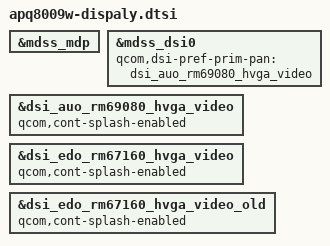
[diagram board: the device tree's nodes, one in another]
/* Copyright (c) 2016,  HUAWEI TECHNOLOGIES CO., LTD.  All rights reserved.
 *
 * This program is free software; you can redistribute it and/or modify
 * it under the terms of the GNU General Public License version 2 and
 * only version 2 as published by the Free Software Foundation.
 *
 * This program is distributed in the hope that it will be useful,
 * but WITHOUT ANY WARRANTY; without even the implied warranty of
 * MERCHANTABILITY or FITNESS FOR A PARTICULAR PURPOSE.  See the
 * GNU General Public License for more details.
 */

#include "dsi-panel-edo-rm67160-hvga-video.dtsi"
#include "dsi-panel-auo-rm69080-hvga-video.dtsi"
#include "dsi-panel-edo-rm67160-hvga-video-old.dtsi"

/*delete the qcom dispaly dtsi*/
&mdss_mdp {
    /delete-node/ dsi_hx8394d_480_vid;
    /delete-node/ dsi_hx8394d_720_vid;
    /delete-node/ dsi_hx8394d_qhd_vid;

    /delete-node/ dsi_auo_cx_qvga_cmd;
    /delete-node/ dsi_auo_qvga_cmd;
    /delete-node/ dsi_hx8394d_480_vid;
    /delete-node/ dsi_hx8394d_720_vid;
    /delete-node/ dsi_hx8394d_qhd_vid;
};


&mdss_dsi0 {
	qcom,dsi-pref-prim-pan = <&dsi_auo_rm69080_hvga_video>;
	/delete-property/ qcom,platform-bklight-en-gpio;
};

&dsi_auo_rm69080_hvga_video{
	qcom,cont-splash-enabled;
};

&dsi_edo_rm67160_hvga_video{
	qcom,cont-splash-enabled;
};

/* TODO: delete old EDO config when deprecated */
&dsi_edo_rm67160_hvga_video_old{
	qcom,cont-splash-enabled;
};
